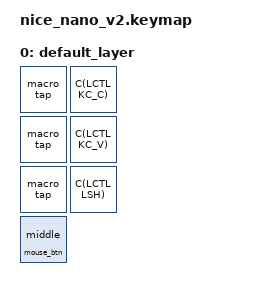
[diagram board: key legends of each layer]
#include <behaviors.dtsi>
#include <dt-bindings/zmk/keys.h>

/ {
    keymap {
        compatible = "zmk,keymap";

        default_layer {
            bindings = <
                &macro_tap C(LCTL KC_C)
                &macro_tap C(LCTL KC_V)
                &macro_tap C(LCTL LSH)
                &mouse_btn middle
            >;
        };
    };
};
